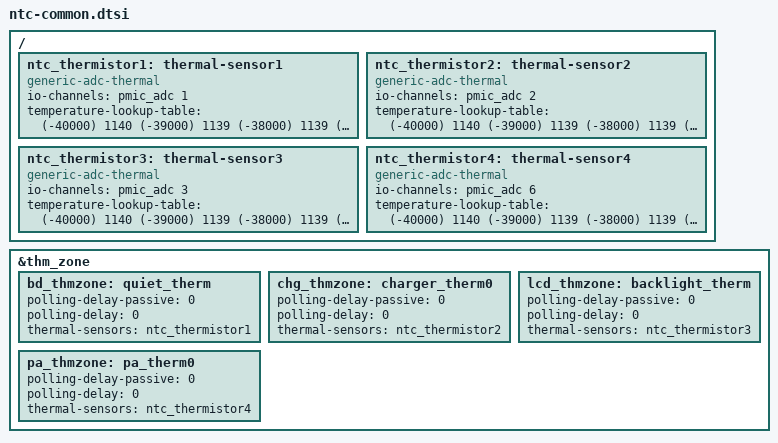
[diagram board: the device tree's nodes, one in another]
// SPDX-License-Identifier: (Licenseref-Unisoc-General-1.0 OR GPL-2.0-only)
/*
 * ntc-common.dtsi - Unisoc platform device
 *
 * Copyright 2022 Unisoc(Shanghai) Technologies Co.Ltd
 *
 * Licensed under the Unisoc General Software License, version 1.0 (the
 * License);
 * you may not use this file except in compliance with the License.
 * You may obtain a copy of the License at
 * https://www.unisoc.com/en_us/license/UNISOC_GENERAL_LICENSE_V1.0-EN_US
 * Software distributed under the License is distributed on an "AS IS" BASIS,
 * WITHOUT WARRANTIES OF ANY KIND, either express or implied.
 * See the Unisoc General Software License, version 1.0 for more details.
 *
 * Alternatively you can use and distribute this file under the terms of the
 * GNU General Public License version 2, provided that it has to be used
 *  (including but not limited to combining, linking) with any other file under
 * the GNU General Public License version 2 on platforms that use Unisoc Chips.
 */

/ {
	ntc_thermistor1:thermal-sensor1 {
		compatible = "generic-adc-thermal";
		#thermal-sensor-cells = <0>;
		io-channels = <&pmic_adc 1>;
		io-channel-names = "sensor-channel";
		temperature-lookup-table = <    (-40000) 1140
						(-39000) 1139
						(-38000) 1139
						(-37000) 1138
						(-36000) 1138
						(-35000) 1136
						(-34000) 1135
						(-33000) 1134
						(-32000) 1133
						(-31000) 1132
						(-30000) 1131
						(-29000) 1130
						(-28000) 1128
						(-27000) 1127
						(-26000) 1125
						(-25000) 1124
						(-24000) 1122
						(-23000) 1120
						(-22000) 1119
						(-21000) 1117
						(-20000) 1115
						(-19000) 1112
						(-18000) 1110
						(-17000) 1108
						(-16000) 1105
						(-15000) 1103
						(-14000) 1100
						(-13000) 1097
						(-12000) 1094
						(-11000) 1091
						(-10000) 1087
						(-9000) 1084
						(-8000) 1080
						(-7000) 1076
						(-6000) 1072
						(-5000) 1068
						(-4000) 1064
						(-3000) 1059
						(-2000) 1054
						(-1000) 1049
						(0) 1044
						1000 1039
						2000 1033
						3000 1028
						4000 1022
						5000 1016
						6000 1009
						7000 1003
						8000 996
						9000 989
						10000 981
						11000 974
						12000 966
						13000 958
						14000 950
						15000 942
						16000 933
						17000 924
						18000 915
						19000 906
						20000 896
						21000 887
						22000 877
						23000 867
						24000 856
						25000 846
						26000 835
						27000 824
						28000 813
						29000 802
						30000 791
						31000 780
						32000 768
						33000 756
						34000 745
						35000 733
						36000 721
						37000 709
						38000 697
						39000 685
						40000 673
						41000 661
						42000 649
						43000 636
						44000 624
						45000 612
						46000 600
						47000 588
						48000 576
						49000 564
						50000 552
						51000 540
						52000 529
						53000 517
						54000 506
						55000 494
						56000 483
						57000 472
						58000 461
						59000 450
						60000 439
						61000 429
						62000 419
						63000 408
						64000 398
						65000 388
						66000 379
						67000 369
						68000 360
						69000 351
						70000 342
						71000 333
						72000 324
						73000 316
						74000 307
						75000 299
						76000 291
						77000 284
						78000 276
						79000 269
						80000 261
						81000 254
						82000 247
						83000 241
						84000 234
						85000 228
						86000 222
						87000 215
						88000 210
						89000 204
						90000 198
						91000 193
						92000 187
						93000 182
						94000 177
						95000 172
						96000 168
						97000 163
						98000 159
						99000 154
						100000 150
						101000 146
						102000 142
						103000 138
						104000 134
						105000 130
						106000 127
						107000 123
						108000 120
						109000 117
						110000 114
						111000 110
						112000 117
						113000 105
						114000 102
						115000 99
						116000 96
						117000 94
						118000 91
						119000 89
						120000 86
						121000 84
						122000 82
						123000 80
						124000 78
						125000 75 >;
	};

	ntc_thermistor2:thermal-sensor2 {
		compatible = "generic-adc-thermal";
		#thermal-sensor-cells = <0>;
		io-channels = <&pmic_adc 2>;
		io-channel-names = "sensor-channel";
		temperature-lookup-table = <    (-40000) 1140
						(-39000) 1139
						(-38000) 1139
						(-37000) 1138
						(-36000) 1138
						(-35000) 1136
						(-34000) 1135
						(-33000) 1134
						(-32000) 1133
						(-31000) 1132
						(-30000) 1131
						(-29000) 1130
						(-28000) 1128
						(-27000) 1127
						(-26000) 1125
						(-25000) 1124
						(-24000) 1122
						(-23000) 1120
						(-22000) 1119
						(-21000) 1117
						(-20000) 1115
						(-19000) 1112
						(-18000) 1110
						(-17000) 1108
						(-16000) 1105
						(-15000) 1103
						(-14000) 1100
						(-13000) 1097
						(-12000) 1094
						(-11000) 1091
						(-10000) 1087
						(-9000) 1084
						(-8000) 1080
						(-7000) 1076
						(-6000) 1072
						(-5000) 1068
						(-4000) 1064
						(-3000) 1059
						(-2000) 1054
						(-1000) 1049
						(0) 1044
						1000 1039
						2000 1033
						3000 1028
						4000 1022
						5000 1016
						6000 1009
						7000 1003
						8000 996
						9000 989
						10000 981
						11000 974
						12000 966
						13000 958
						14000 950
						15000 942
						16000 933
						17000 924
						18000 915
						19000 906
						20000 896
						21000 887
						22000 877
						23000 867
						24000 856
						25000 846
						26000 835
						27000 824
						28000 813
						29000 802
						30000 791
						31000 780
						32000 768
						33000 756
						34000 745
						35000 733
						36000 721
						37000 709
						38000 697
						39000 685
						40000 673
						41000 661
						42000 649
						43000 636
						44000 624
						45000 612
						46000 600
						47000 588
						48000 576
						49000 564
						50000 552
						51000 540
						52000 529
						53000 517
						54000 506
						55000 494
						56000 483
						57000 472
						58000 461
						59000 450
						60000 439
						61000 429
						62000 419
						63000 408
						64000 398
						65000 388
						66000 379
						67000 369
						68000 360
						69000 351
						70000 342
						71000 333
						72000 324
						73000 316
						74000 307
						75000 299
						76000 291
						77000 284
						78000 276
						79000 269
						80000 261
						81000 254
						82000 247
						83000 241
						84000 234
						85000 228
						86000 222
						87000 215
						88000 210
						89000 204
						90000 198
						91000 193
						92000 187
						93000 182
						94000 177
						95000 172
						96000 168
						97000 163
						98000 159
						99000 154
						100000 150
						101000 146
						102000 142
						103000 138
						104000 134
						105000 130
						106000 127
						107000 123
						108000 120
						109000 117
						110000 114
						111000 110
						112000 117
						113000 105
						114000 102
						115000 99
						116000 96
						117000 94
						118000 91
						119000 89
						120000 86
						121000 84
						122000 82
						123000 80
						124000 78
						125000 75 >;
	};

	ntc_thermistor3:thermal-sensor3 {
		compatible = "generic-adc-thermal";
		#thermal-sensor-cells = <0>;
		io-channels = <&pmic_adc 3>;
		io-channel-names = "sensor-channel";
		temperature-lookup-table = <    (-40000) 1140
						(-39000) 1139
						(-38000) 1139
						(-37000) 1138
						(-36000) 1138
						(-35000) 1136
						(-34000) 1135
						(-33000) 1134
						(-32000) 1133
						(-31000) 1132
						(-30000) 1131
						(-29000) 1130
						(-28000) 1128
						(-27000) 1127
						(-26000) 1125
						(-25000) 1124
						(-24000) 1122
						(-23000) 1120
						(-22000) 1119
						(-21000) 1117
						(-20000) 1115
						(-19000) 1112
						(-18000) 1110
						(-17000) 1108
						(-16000) 1105
						(-15000) 1103
						(-14000) 1100
						(-13000) 1097
						(-12000) 1094
						(-11000) 1091
						(-10000) 1087
						(-9000) 1084
						(-8000) 1080
						(-7000) 1076
						(-6000) 1072
						(-5000) 1068
						(-4000) 1064
						(-3000) 1059
						(-2000) 1054
						(-1000) 1049
						(0) 1044
						1000 1039
						2000 1033
						3000 1028
						4000 1022
						5000 1016
						6000 1009
						7000 1003
						8000 996
						9000 989
						10000 981
						11000 974
						12000 966
						13000 958
						14000 950
						15000 942
						16000 933
						17000 924
						18000 915
						19000 906
						20000 896
						21000 887
						22000 877
						23000 867
						24000 856
						25000 846
						26000 835
						27000 824
						28000 813
						29000 802
						30000 791
						31000 780
						32000 768
						33000 756
						34000 745
						35000 733
						36000 721
						37000 709
						38000 697
						39000 685
						40000 673
						41000 661
						42000 649
						43000 636
						44000 624
						45000 612
						46000 600
						47000 588
						48000 576
						49000 564
						50000 552
						51000 540
						52000 529
						53000 517
						54000 506
						55000 494
						56000 483
						57000 472
						58000 461
						59000 450
						60000 439
						61000 429
						62000 419
						63000 408
						64000 398
						65000 388
						66000 379
						67000 369
						68000 360
						69000 351
						70000 342
						71000 333
						72000 324
						73000 316
						74000 307
						75000 299
						76000 291
						77000 284
						78000 276
						79000 269
						80000 261
						81000 254
						82000 247
						83000 241
						84000 234
						85000 228
						86000 222
						87000 215
						88000 210
						89000 204
						90000 198
						91000 193
						92000 187
						93000 182
						94000 177
						95000 172
						96000 168
						97000 163
						98000 159
						99000 154
						100000 150
						101000 146
						102000 142
						103000 138
						104000 134
						105000 130
						106000 127
						107000 123
						108000 120
						109000 117
						110000 114
						111000 110
						112000 117
						113000 105
						114000 102
						115000 99
						116000 96
						117000 94
						118000 91
						119000 89
						120000 86
						121000 84
						122000 82
						123000 80
						124000 78
						125000 75 >;
	};

	ntc_thermistor4:thermal-sensor4 {
		compatible = "generic-adc-thermal";
		#thermal-sensor-cells = <0>;
		io-channels = <&pmic_adc 6>;
		io-channel-names = "sensor-channel";
				temperature-lookup-table = <    (-40000) 1140
						(-39000) 1139
						(-38000) 1139
						(-37000) 1138
						(-36000) 1138
						(-35000) 1136
						(-34000) 1135
						(-33000) 1134
						(-32000) 1133
						(-31000) 1132
						(-30000) 1131
						(-29000) 1130
						(-28000) 1128
						(-27000) 1127
						(-26000) 1125
						(-25000) 1124
						(-24000) 1122
						(-23000) 1120
						(-22000) 1119
						(-21000) 1117
						(-20000) 1115
						(-19000) 1112
						(-18000) 1110
						(-17000) 1108
						(-16000) 1105
						(-15000) 1103
						(-14000) 1100
						(-13000) 1097
						(-12000) 1094
						(-11000) 1091
						(-10000) 1087
						(-9000) 1084
						(-8000) 1080
						(-7000) 1076
						(-6000) 1072
						(-5000) 1068
						(-4000) 1064
						(-3000) 1059
						(-2000) 1054
						(-1000) 1049
						(0) 1044
						1000 1039
						2000 1033
						3000 1028
						4000 1022
						5000 1016
						6000 1009
						7000 1003
						8000 996
						9000 989
						10000 981
						11000 974
						12000 966
						13000 958
						14000 950
						15000 942
						16000 933
						17000 924
						18000 915
						19000 906
						20000 896
						21000 887
						22000 877
						23000 867
						24000 856
						25000 846
						26000 835
						27000 824
						28000 813
						29000 802
						30000 791
						31000 780
						32000 768
						33000 756
						34000 745
						35000 733
						36000 721
						37000 709
						38000 697
						39000 685
						40000 673
						41000 661
						42000 649
						43000 636
						44000 624
						45000 612
						46000 600
						47000 588
						48000 576
						49000 564
						50000 552
						51000 540
						52000 529
						53000 517
						54000 506
						55000 494
						56000 483
						57000 472
						58000 461
						59000 450
						60000 439
						61000 429
						62000 419
						63000 408
						64000 398
						65000 388
						66000 379
						67000 369
						68000 360
						69000 351
						70000 342
						71000 333
						72000 324
						73000 316
						74000 307
						75000 299
						76000 291
						77000 284
						78000 276
						79000 269
						80000 261
						81000 254
						82000 247
						83000 241
						84000 234
						85000 228
						86000 222
						87000 215
						88000 210
						89000 204
						90000 198
						91000 193
						92000 187
						93000 182
						94000 177
						95000 172
						96000 168
						97000 163
						98000 159
						99000 154
						100000 150
						101000 146
						102000 142
						103000 138
						104000 134
						105000 130
						106000 127
						107000 123
						108000 120
						109000 117
						110000 114
						111000 110
						112000 117
						113000 105
						114000 102
						115000 99
						116000 96
						117000 94
						118000 91
						119000 89
						120000 86
						121000 84
						122000 82
						123000 80
						124000 78
						125000 75 >;
	};
};

&thm_zone {
	bd_thmzone: quiet_therm {
		polling-delay-passive = <0>;
		polling-delay = <0>;
		thermal-sensors = <&ntc_thermistor1>;
	};

	chg_thmzone: charger_therm0 {
		polling-delay-passive = <0>;
		polling-delay = <0>;
		thermal-sensors = <&ntc_thermistor2>;
	};

	lcd_thmzone: backlight_therm {
		polling-delay-passive = <0>;
		polling-delay = <0>;
		thermal-sensors = <&ntc_thermistor3>;
	};

	pa_thmzone: pa_therm0 {
		polling-delay-passive = <0>;
		polling-delay = <0>;
		thermal-sensors = <&ntc_thermistor4>;
	};
};
